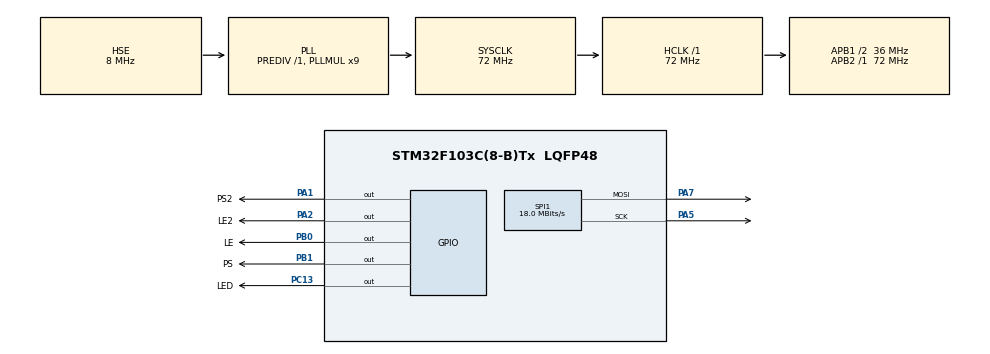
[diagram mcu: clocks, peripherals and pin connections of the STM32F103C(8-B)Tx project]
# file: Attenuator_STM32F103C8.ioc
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Mcu.Family=STM32F1
Mcu.Name=STM32F103C(8-B)Tx
Mcu.Package=LQFP48
NVIC.PriorityGroup=NVIC_PRIORITYGROUP_4
PA1.GPIO_Label=PS2
PA1.Signal=GPIO_Output
PA13.Mode=Serial_Wire
PA13.Signal=SYS_JTMS-SWDIO
PA14.Mode=Serial_Wire
PA14.Signal=SYS_JTCK-SWCLK
PA2.GPIO_Label=LE2
PA2.Signal=GPIO_Output
PA5.Mode=TX_Only_Simplex_Unidirect_Master
PA5.Signal=SPI1_SCK
PA7.Mode=TX_Only_Simplex_Unidirect_Master
PA7.Signal=SPI1_MOSI
PB0.GPIO_Label=LE
PB0.Signal=GPIO_Output
PB1.GPIO_Label=PS
PB1.Signal=GPIO_Output
PC13-TAMPER-RTC.GPIO_Label=LED
PC13-TAMPER-RTC.Signal=GPIO_Output
PD0-OSC_IN.Mode=HSE-External-Oscillator
PD0-OSC_IN.Signal=RCC_OSC_IN
PD1-OSC_OUT.Mode=HSE-External-Oscillator
PD1-OSC_OUT.Signal=RCC_OSC_OUT
ProjectManager.HeapSize=0x200
ProjectManager.StackSize=0x400
ProjectManager.TargetToolchain=STM32CubeIDE
RCC.AHBFreq_Value=72000000
RCC.APB1CLKDivider=RCC_HCLK_DIV2
RCC.APB1Freq_Value=36000000
RCC.APB1TimFreq_Value=72000000
RCC.APB2Freq_Value=72000000
RCC.APB2TimFreq_Value=72000000
RCC.HCLKFreq_Value=72000000
RCC.PLLMUL=RCC_PLL_MUL9
RCC.PLLSourceVirtual=RCC_PLLSOURCE_HSE
RCC.SYSCLKFreq_VALUE=72000000
RCC.SYSCLKSource=RCC_SYSCLKSOURCE_PLLCLK
RCC.USBFreq_Value=72000000
SPI1.BaudRatePrescaler=SPI_BAUDRATEPRESCALER_4
SPI1.CalculateBaudRate=18.0 MBits/s
SPI1.Direction=SPI_DIRECTION_2LINES
SPI1.Mode=SPI_MODE_MASTER
SPI1.VirtualType=VM_MASTER
board=custom

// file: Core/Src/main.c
/* USER CODE BEGIN Header */
/**
 ******************************************************************************
 * @file           : main.c
 * @brief          : Main program body
 ******************************************************************************
 * @attention
 *
 * Copyright (c) 2025 STMicroelectronics.
 * All rights reserved.
 *
 * This software is licensed under terms that can be found in the LICENSE file
 * in the root directory of this software component.
 * If no LICENSE file comes with this software, it is provided AS-IS.
 *
 ******************************************************************************
 */
/* USER CODE END Header */
#include "main.h"
#include "spi.h"
#include "gpio.h"

/* USER CODE BEGIN Includes */
#include "Attenuator.h" // 包含衰减器头文件
/* USER CODE END Includes */

/* USER CODE BEGIN PV */
Attenuator_HandleTypeDef attenuator1; // 定义衰减器1句柄
Attenuator_HandleTypeDef attenuator2; // 定义衰减器2句柄
/* USER CODE END PV */

void SystemClock_Config(void);

int main(void)
{

  /* MCU Configuration--------------------------------------------------------*/

  /* Reset of all peripherals, Initializes the Flash interface and the Systick. */
  HAL_Init();

  /* Configure the system clock */
  SystemClock_Config();

  /* Initialize all configured peripherals */
  MX_GPIO_Init();
  MX_SPI1_Init();
  /* USER CODE BEGIN 2 */
  // 初始化衰减器并设置初始衰减值为 10.5 dB
  Attenuator_Init(&attenuator1, &hspi1, PS_GPIO_Port, PS_Pin, LE_GPIO_Port, LE_Pin);
  Attenuator_Init(&attenuator2, &hspi1, PS2_GPIO_Port, PS2_Pin, LE2_GPIO_Port, LE2_Pin);
  Attenuator_SetAttenuation_SPI(&attenuator1, 20);
  /* USER CODE END 2 */

  /* Infinite loop */
  /* USER CODE BEGIN WHILE */
  while (1)
  {
    HAL_GPIO_TogglePin(LED_GPIO_Port, LED_Pin); // Toggle the LED pin
    HAL_Delay(500);
    // 遍历 PE43711 (0.25dB 步进, 0 - 31.75dB, 共 128 步)
    for (int i = 0; i <= 127; i++)
    {
      Attenuator_PE43711_SetAttenuation_SPI(&attenuator1, i * 0.25f);
      HAL_Delay(50);
    }
    // 遍历 HMC624A/PE4302 (0.5dB 步进, 0 - 31.5dB, 共 64 步)
    for (int i = 0; i <= 63; i++)
    {
      Attenuator_SetAttenuation_SPI(&attenuator2, i * 0.5f);
      HAL_Delay(50);
    }
    /* USER CODE END WHILE */

  }
}

void SystemClock_Config(void)
{
  RCC_OscInitTypeDef RCC_OscInitStruct = {0};
  RCC_ClkInitTypeDef RCC_ClkInitStruct = {0};

  /** Initializes the RCC Oscillators according to the specified parameters
   * in the RCC_OscInitTypeDef structure.
   */
  RCC_OscInitStruct.OscillatorType = RCC_OSCILLATORTYPE_HSE;
  RCC_OscInitStruct.HSEState = RCC_HSE_ON;
  RCC_OscInitStruct.HSEPredivValue = RCC_HSE_PREDIV_DIV1;
  RCC_OscInitStruct.HSIState = RCC_HSI_ON;
  RCC_OscInitStruct.PLL.PLLState = RCC_PLL_ON;
  RCC_OscInitStruct.PLL.PLLSource = RCC_PLLSOURCE_HSE;
  RCC_OscInitStruct.PLL.PLLMUL = RCC_PLL_MUL9;
  if (HAL_RCC_OscConfig(&RCC_OscInitStruct) != HAL_OK)
  {
    Error_Handler();
  }

  /** Initializes the CPU, AHB and APB buses clocks
   */
  RCC_ClkInitStruct.ClockType = RCC_CLOCKTYPE_HCLK | RCC_CLOCKTYPE_SYSCLK | RCC_CLOCKTYPE_PCLK1 | RCC_CLOCKTYPE_PCLK2;
  RCC_ClkInitStruct.SYSCLKSource = RCC_SYSCLKSOURCE_PLLCLK;
  RCC_ClkInitStruct.AHBCLKDivider = RCC_SYSCLK_DIV1;
  RCC_ClkInitStruct.APB1CLKDivider = RCC_HCLK_DIV2;
  RCC_ClkInitStruct.APB2CLKDivider = RCC_HCLK_DIV1;

  if (HAL_RCC_ClockConfig(&RCC_ClkInitStruct, FLASH_LATENCY_2) != HAL_OK)
  {
    Error_Handler();
  }
}

void Error_Handler(void)
{
  __disable_irq();
  while (1)
  {
  }
}
